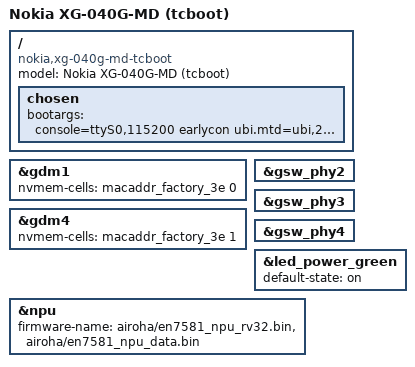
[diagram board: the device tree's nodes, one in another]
// SPDX-License-Identifier: GPL-2.0-only OR MIT

#include "an7581-nokia_xg-040g-md-common.dtsi"
#include "an7581-nokia-tcboot-parts.dtsi"

/ {
	model = "Nokia XG-040G-MD (tcboot)";
	compatible = "nokia,xg-040g-md-tcboot", "airoha,an7581",
		     "airoha,en7581";

	chosen {
		bootargs = "console=ttyS0,115200 earlycon ubi.mtd=ubi,2048 rootfstype=squashfs ubi.block=0,rootfs ro root=/dev/ubiblock0_3 init=/etc/preinit";
	};
};

&gdm1 {
	nvmem-cells = <&macaddr_factory_3e 0>;
};

&gdm4 {
	nvmem-cells = <&macaddr_factory_3e 1>;
};

&gsw_phy2 {
	/delete-property/ interrupts;
};

&gsw_phy3 {
	/delete-property/ interrupts;
};

&gsw_phy4 {
	/delete-property/ interrupts;
};

&led_power_green {
	default-state = "on";
};

&npu {
	firmware-name = "airoha/en7581_npu_rv32.bin",
			"airoha/en7581_npu_data.bin";
};
